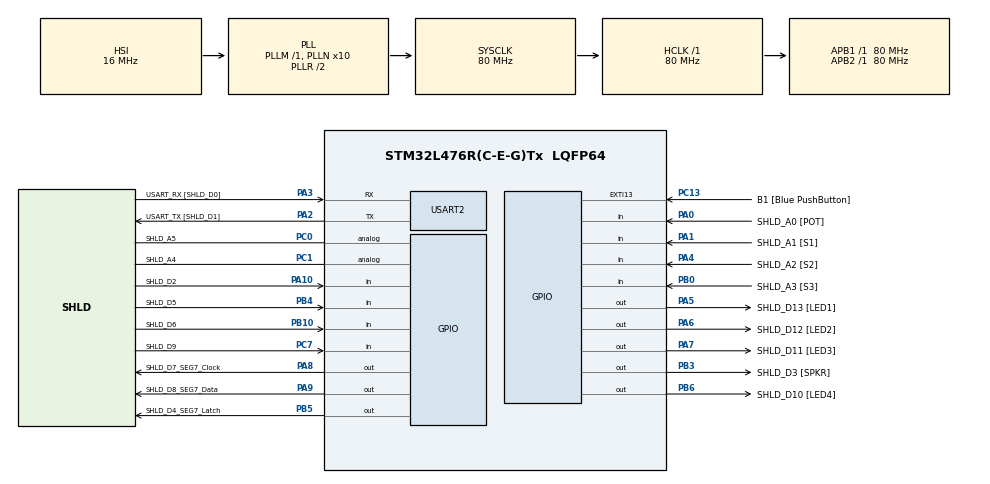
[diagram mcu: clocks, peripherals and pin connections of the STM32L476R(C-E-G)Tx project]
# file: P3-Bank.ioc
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FREERTOS.BinarySemaphores01=myBinarySem01,Dynamic,NULL
FREERTOS.Tasks01=defaultTask,24,128,StartDefaultTask,Default,NULL,Dynamic,NULL,NULL
Mcu.Family=STM32L4
Mcu.Name=STM32L476R(C-E-G)Tx
Mcu.Package=LQFP64
NVIC.PriorityGroup=NVIC_PRIORITYGROUP_4
NVIC.TIM5_IRQn=true\:15\:0\:false\:false\:true\:false\:false\:true\:true
NVIC.TimeBase=TIM5_IRQn
NVIC.TimeBaseIP=TIM5
PA0.GPIO_Label=SHLD_A0 [POT]
PA0.Signal=GPIO_Input
PA1.GPIO_Label=SHLD_A1 [S1]
PA1.GPIO_PuPd=GPIO_PULLUP
PA1.Signal=GPIO_Input
PA10.GPIO_Label=SHLD_D2
PA10.Signal=GPIO_Input
PA13\ (JTMS-SWDIO).GPIO_Label=TMS
PA13\ (JTMS-SWDIO).Mode=Serial_Wire
PA13\ (JTMS-SWDIO).Signal=SYS_JTMS-SWDIO
PA14\ (JTCK-SWCLK).GPIO_Label=TCK
PA14\ (JTCK-SWCLK).Mode=Serial_Wire
PA14\ (JTCK-SWCLK).Signal=SYS_JTCK-SWCLK
PA2.GPIO_Label=USART_TX [SHLD_D1]
PA2.GPIO_Mode=GPIO_MODE_AF_PP
PA2.GPIO_PuPd=GPIO_NOPULL
PA2.GPIO_Speed=GPIO_SPEED_FREQ_VERY_HIGH
PA2.Mode=Asynchronous
PA2.Signal=USART2_TX
PA3.GPIO_Label=USART_RX [SHLD_D0]
PA3.GPIO_Mode=GPIO_MODE_AF_PP
PA3.GPIO_PuPd=GPIO_NOPULL
PA3.GPIO_Speed=GPIO_SPEED_FREQ_VERY_HIGH
PA3.Mode=Asynchronous
PA3.Signal=USART2_RX
PA4.GPIO_Label=SHLD_A2 [S2]
PA4.GPIO_PuPd=GPIO_PULLUP
PA4.Signal=GPIO_Input
PA5.GPIO_Label=SHLD_D13 [LED1]
PA5.PinState=GPIO_PIN_SET
PA5.Signal=GPIO_Output
PA6.GPIO_Label=SHLD_D12 [LED2]
PA6.PinState=GPIO_PIN_SET
PA6.Signal=GPIO_Output
PA7.GPIO_Label=SHLD_D11 [LED3]
PA7.PinState=GPIO_PIN_SET
PA7.Signal=GPIO_Output
PA8.GPIO_Label=SHLD_D7_SEG7_Clock
PA8.PinState=GPIO_PIN_SET
PA8.Signal=GPIO_Output
PA9.GPIO_Label=SHLD_D8_SEG7_Data
PA9.GPIO_ModeDefaultOutputPP=GPIO_MODE_OUTPUT_PP
PA9.GPIO_Speed=GPIO_SPEED_FREQ_MEDIUM
PA9.PinState=GPIO_PIN_SET
PA9.Signal=GPIO_Output
PB0.GPIO_Label=SHLD_A3 [S3]
PB0.GPIO_PuPd=GPIO_PULLUP
PB0.Signal=GPIO_Input
PB10.GPIO_Label=SHLD_D6
PB10.Signal=GPIO_Input
PB3\ (JTDO-TRACESWO).GPIO_Label=SHLD_D3 [SPKR]
PB3\ (JTDO-TRACESWO).GPIO_ModeDefaultOutputPP=GPIO_MODE_OUTPUT_OD
PB3\ (JTDO-TRACESWO).GPIO_Speed=GPIO_SPEED_FREQ_HIGH
PB3\ (JTDO-TRACESWO).PinState=GPIO_PIN_SET
PB3\ (JTDO-TRACESWO).Signal=GPIO_Output
PB4\ (NJTRST).GPIO_Label=SHLD_D5
PB4\ (NJTRST).Signal=GPIO_Input
PB5.GPIO_Label=SHLD_D4_SEG7_Latch
PB5.GPIO_Speed=GPIO_SPEED_FREQ_HIGH
PB5.PinState=GPIO_PIN_SET
PB5.Signal=GPIO_Output
PB6.GPIO_FM6=__NULL
PB6.GPIO_Label=SHLD_D10 [LED4]
PB6.PinState=GPIO_PIN_SET
PB6.Signal=GPIO_Output
PB8.GPIO_Label=SHLD_D15
PB8.Signal=I2C1_SCL
PB9.GPIO_Label=SHLD_D14
PB9.Signal=I2C1_SDA
PC0.GPIO_Label=SHLD_A5
PC0.Signal=GPIO_Analog
PC1.GPIO_Label=SHLD_A4
PC1.Signal=SharedAnalog_PC1
PC13.GPIO_Label=B1 [Blue PushButton]
PC13.GPIO_ModeDefaultEXTI=GPIO_MODE_IT_FALLING
PC13.GPIO_PuPd=GPIO_NOPULL
PC13.Signal=GPXTI13
PC14-OSC32_IN\ (PC14).Mode=LSE-External-Oscillator
PC14-OSC32_IN\ (PC14).Signal=RCC_OSC32_IN
PC15-OSC32_OUT\ (PC15).Mode=LSE-External-Oscillator
PC15-OSC32_OUT\ (PC15).Signal=RCC_OSC32_OUT
PC7.GPIO_Label=SHLD_D9
PC7.Signal=GPIO_Input
PH0-OSC_IN\ (PH0).Signal=RCC_OSC_IN
PH1-OSC_OUT\ (PH1).Signal=RCC_OSC_OUT
ProjectManager.HeapSize=0x200
ProjectManager.StackSize=0x400
ProjectManager.TargetToolchain=Makefile
RCC.ADCFreq_Value=64000000
RCC.AHBFreq_Value=80000000
RCC.APB1Freq_Value=80000000
RCC.APB1TimFreq_Value=80000000
RCC.APB2Freq_Value=80000000
RCC.APB2TimFreq_Value=80000000
RCC.CortexFreq_Value=80000000
RCC.HCLKFreq_Value=80000000
RCC.HSE_VALUE=8000000
RCC.HSI_VALUE=16000000
RCC.MSI_VALUE=4000000
RCC.PLLN=10
RCC.PLLSAI1Q=RCC_PLLQ_DIV4
RCC.PLLSourceVirtual=RCC_PLLSOURCE_HSI
RCC.PREFETCH_ENABLE=1
RCC.SYSCLKFreq_VALUE=80000000
RCC.SYSCLKSource=RCC_SYSCLKSOURCE_PLLCLK
RCC.USBFreq_Value=32000000
RCC.VCOOutputFreq_Value=160000000
SH.SharedAnalog_PC1.0=GPIO_Analog
SH.SharedAnalog_PC1.1=ADC1_IN2
USART2.VirtualMode-Asynchronous=VM_ASYNC
VP_FREERTOS_VS_CMSIS_V2.Mode=CMSIS_V2
VP_RNG_VS_RNG.Mode=RNG_Activate
VP_SYS_VS_tim5.Mode=TIM5
board=NUCLEO-L476RG

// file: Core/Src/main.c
/* USER CODE BEGIN Header */
/**
 ******************************************************************************
 * @file           : main.c
 * @brief          : Main program body
 ******************************************************************************
 * @attention
 *
 * Copyright (c) 2024 STMicroelectronics.
 * All rights reserved.
 *
 * This software is licensed under terms that can be found in the LICENSE file
 * in the root directory of this software component.
 * If no LICENSE file comes with this software, it is provided AS-IS.
 *
 ******************************************************************************
 */
/* USER CODE END Header */
#include "main.h"
#include "cmsis_os.h"
#include "gpio.h"
#include "rng.h"
#include "shield.h"
#include "timer.h"
#include "usart.h"
#include "utils.h"

void SystemClock_Config(void);
void MX_FREERTOS_Init(void);

int main(void) {

  /* MCU Configuration--------------------------------------------------------*/

  /* Reset of all peripherals, Initializes the Flash interface and the Systick.
   */
  HAL_Init();

  /* Configure the system clock */
  SystemClock_Config();

  /* USER CODE BEGIN SysInit */

  // Initalize 3 SHLD Buttons (A1, A2, A3)
  TIM2_Init();
  SHLD_Button_Init(SHLD_A1_GPIO_Port, Teller1_Pin | Teller2_Pin);
  SHLD_Button_Init(SHLD_A3_GPIO_Port, Teller3_Pin);

  /* USER CODE END SysInit */

  /* Initialize all configured peripherals */
  MX_GPIO_Init();
  MX_USART2_UART_Init();
  MX_RNG_Init();

  /* Init scheduler */
  osKernelInitialize();

  /* Call init function for freertos objects (in freertos.c) */
  MX_FREERTOS_Init();

  /* Start scheduler */
  TIM_Start();
  osKernelStart();

  /* We should never get here as control is now taken by the scheduler */
  /* Infinite loop */
  while (1) {

  }
}

void SystemClock_Config(void) {
  RCC_OscInitTypeDef RCC_OscInitStruct = {0};
  RCC_ClkInitTypeDef RCC_ClkInitStruct = {0};

  /** Configure the main internal regulator output voltage
   */
  if (HAL_PWREx_ControlVoltageScaling(PWR_REGULATOR_VOLTAGE_SCALE1) != HAL_OK) {
    Error_Handler();
  }

  /** Initializes the RCC Oscillators according to the specified parameters
   * in the RCC_OscInitTypeDef structure.
   */
  RCC_OscInitStruct.OscillatorType = RCC_OSCILLATORTYPE_HSI;
  RCC_OscInitStruct.HSIState = RCC_HSI_ON;
  RCC_OscInitStruct.HSICalibrationValue = RCC_HSICALIBRATION_DEFAULT;
  RCC_OscInitStruct.PLL.PLLState = RCC_PLL_ON;
  RCC_OscInitStruct.PLL.PLLSource = RCC_PLLSOURCE_HSI;
  RCC_OscInitStruct.PLL.PLLM = 1;
  RCC_OscInitStruct.PLL.PLLN = 10;
  RCC_OscInitStruct.PLL.PLLP = RCC_PLLP_DIV7;
  RCC_OscInitStruct.PLL.PLLQ = RCC_PLLQ_DIV2;
  RCC_OscInitStruct.PLL.PLLR = RCC_PLLR_DIV2;
  if (HAL_RCC_OscConfig(&RCC_OscInitStruct) != HAL_OK) {
    Error_Handler();
  }

  /** Initializes the CPU, AHB and APB buses clocks
   */
  RCC_ClkInitStruct.ClockType = RCC_CLOCKTYPE_HCLK | RCC_CLOCKTYPE_SYSCLK |
                                RCC_CLOCKTYPE_PCLK1 | RCC_CLOCKTYPE_PCLK2;
  RCC_ClkInitStruct.SYSCLKSource = RCC_SYSCLKSOURCE_PLLCLK;
  RCC_ClkInitStruct.AHBCLKDivider = RCC_SYSCLK_DIV1;
  RCC_ClkInitStruct.APB1CLKDivider = RCC_HCLK_DIV1;
  RCC_ClkInitStruct.APB2CLKDivider = RCC_HCLK_DIV1;

  if (HAL_RCC_ClockConfig(&RCC_ClkInitStruct, FLASH_LATENCY_4) != HAL_OK) {
    Error_Handler();
  }
}

void HAL_TIM_PeriodElapsedCallback(TIM_HandleTypeDef *htim) {
  if (htim->Instance == TIM5) {
    HAL_IncTick();
  }
}

void Error_Handler(void) {
  __disable_irq();
  while (1) {
  }
}

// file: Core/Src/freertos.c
/* USER CODE BEGIN Header */
/**
 ******************************************************************************
 * File Name          : freertos.c
 * Description        : Code for freertos applications
 ******************************************************************************
 * @attention
 *
 * Copyright (c) 2024 STMicroelectronics.
 * All rights reserved.
 *
 * This software is licensed under terms that can be found in the LICENSE file
 * in the root directory of this software component.
 * If no LICENSE file comes with this software, it is provided AS-IS.
 *
 ******************************************************************************
 */
/* USER CODE END Header */

#include "FreeRTOS.h"
#include "bank.h"
#include "cmsis_os2.h"
#include "display.h"
#include "task.h"
#include "utils.h"

#define NEW_TASK(name, func, arg, handler, error_handler)                      \
  if (xTaskCreate(func, name, 128, arg, osPriorityHigh, handler) != pdPASS) {  \
    error_handler;                                                             \
  }

TaskHandle_t bank_task_handler;
TaskHandle_t customer_queue_task_handler;
TaskHandle_t display_task_handler;

void bank_task(void *x);
void customer_task(void *x);
void teller_task(void *x);

void MX_FREERTOS_Init(void); /* (MISRA C 2004 rule 8.1) */

void MX_FREERTOS_Init(void) {

  const xSemaphoreHandle bank_semaphore = xSemaphoreCreateMutex();

  bank *manager = bank_init();
  manager->bank_handler = bank_semaphore;

  NEW_TASK("BankTask", bank_task, manager, &bank_task_handler,
           error("Failed to create bank task"));

  NEW_TASK("QueueTask", customer_task, manager, &customer_queue_task_handler,
           error("Failed to create customer queue task"));

  NEW_TASK("DisplayTask", display_task, manager, &display_task_handler,
           error("Failed to create display task"))

  for (int i = 0; i < NUM_TELLERS; i++) {
    teller *tllr = manager->tellers[i];
    TaskHandle_t teller_task_handler;
    NEW_TASK(format("TellerTask%d", i + 1), teller_task, tllr,
             &teller_task_handler,
             error(format("Failed to create teller %d task", i + 1)));
  }
}
